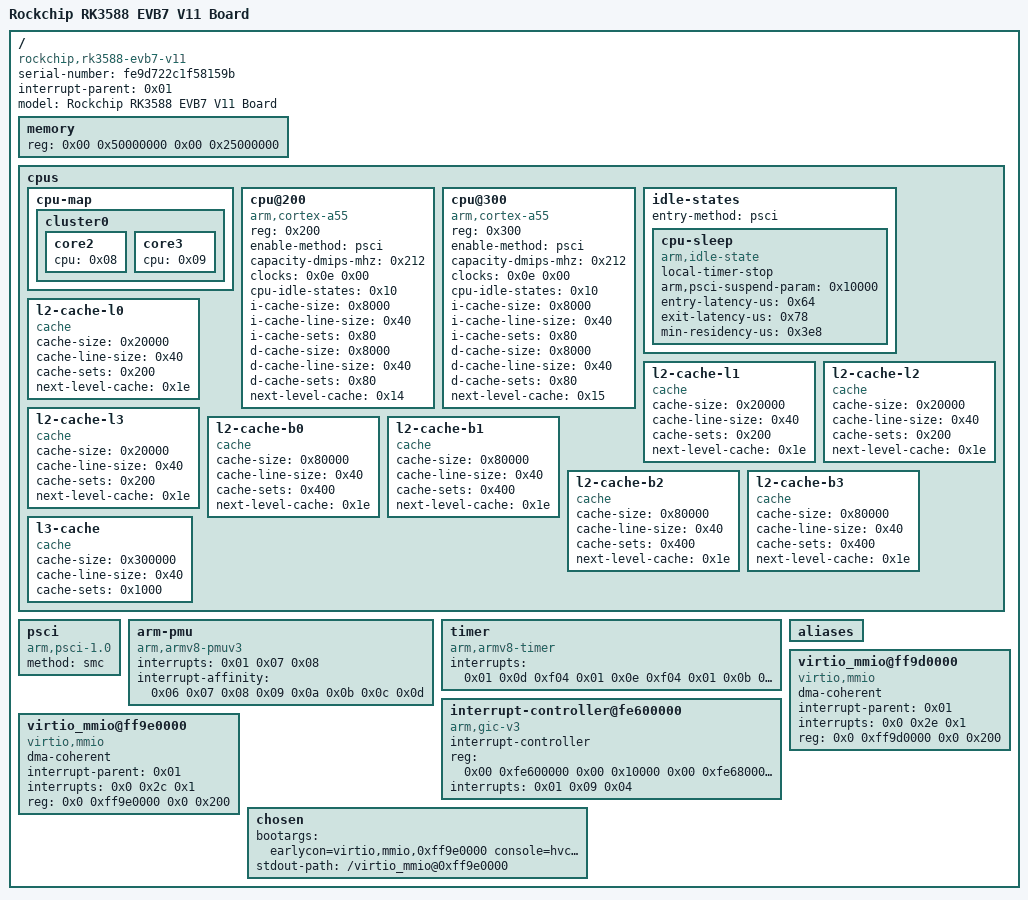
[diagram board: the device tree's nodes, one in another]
/dts-v1/;

/memreserve/	0x0000000008300000 0x0000000000047000;
/ {
	serial-number = "fe9d722c1f58159b";
	compatible = "rockchip,rk3588-evb7-v11\0rockchip,rk3588";
	interrupt-parent = <0x01>;
	#address-cells = <0x02>;
	#size-cells = <0x02>;
	model = "Rockchip RK3588 EVB7 V11 Board";

	memory {
		reg = <0x00 0x50000000 0x00 0x25000000>;
		device_type = "memory";
	};

	cpus {
		#address-cells = <0x01>;
		#size-cells = <0x00>;

		cpu-map {
			cluster0 {
				core2 {
					cpu = <0x08>;
				};
				core3 {
					cpu = <0x09>;
				};
			};
		};

		cpu@200 {
			device_type = "cpu";
			compatible = "arm,cortex-a55";
			reg = <0x200>;
			enable-method = "psci";
			capacity-dmips-mhz = <0x212>;
			clocks = <0x0e 0x00>;
			cpu-idle-states = <0x10>;
			i-cache-size = <0x8000>;
			i-cache-line-size = <0x40>;
			i-cache-sets = <0x80>;
			d-cache-size = <0x8000>;
			d-cache-line-size = <0x40>;
			d-cache-sets = <0x80>;
			next-level-cache = <0x14>;
			phandle = <0x08>;
		};

		cpu@300 {
			device_type = "cpu";
			compatible = "arm,cortex-a55";
			reg = <0x300>;
			enable-method = "psci";
			capacity-dmips-mhz = <0x212>;
			clocks = <0x0e 0x00>;
			cpu-idle-states = <0x10>;
			i-cache-size = <0x8000>;
			i-cache-line-size = <0x40>;
			i-cache-sets = <0x80>;
			d-cache-size = <0x8000>;
			d-cache-line-size = <0x40>;
			d-cache-sets = <0x80>;
			next-level-cache = <0x15>;
			phandle = <0x09>;
		};

		idle-states {
			entry-method = "psci";
			cpu-sleep {
				compatible = "arm,idle-state";
				local-timer-stop;
				arm,psci-suspend-param = <0x10000>;
				entry-latency-us = <0x64>;
				exit-latency-us = <0x78>;
				min-residency-us = <0x3e8>;
				phandle = <0x10>;
			};
		};

		l2-cache-l0 {
			compatible = "cache";
			cache-size = <0x20000>;
			cache-line-size = <0x40>;
			cache-sets = <0x200>;
			next-level-cache = <0x1e>;
			phandle = <0x11>;
		};

		l2-cache-l1 {
			compatible = "cache";
			cache-size = <0x20000>;
			cache-line-size = <0x40>;
			cache-sets = <0x200>;
			next-level-cache = <0x1e>;
			phandle = <0x13>;
		};

		l2-cache-l2 {
			compatible = "cache";
			cache-size = <0x20000>;
			cache-line-size = <0x40>;
			cache-sets = <0x200>;
			next-level-cache = <0x1e>;
			phandle = <0x14>;
		};

		l2-cache-l3 {
			compatible = "cache";
			cache-size = <0x20000>;
			cache-line-size = <0x40>;
			cache-sets = <0x200>;
			next-level-cache = <0x1e>;
			phandle = <0x15>;
		};

		l2-cache-b0 {
			compatible = "cache";
			cache-size = <0x80000>;
			cache-line-size = <0x40>;
			cache-sets = <0x400>;
			next-level-cache = <0x1e>;
			phandle = <0x17>;
		};

		l2-cache-b1 {
			compatible = "cache";
			cache-size = <0x80000>;
			cache-line-size = <0x40>;
			cache-sets = <0x400>;
			next-level-cache = <0x1e>;
			phandle = <0x19>;
		};

		l2-cache-b2 {
			compatible = "cache";
			cache-size = <0x80000>;
			cache-line-size = <0x40>;
			cache-sets = <0x400>;
			next-level-cache = <0x1e>;
			phandle = <0x1b>;
		};

		l2-cache-b3 {
			compatible = "cache";
			cache-size = <0x80000>;
			cache-line-size = <0x40>;
			cache-sets = <0x400>;
			next-level-cache = <0x1e>;
			phandle = <0x1d>;
		};

		l3-cache {
			compatible = "cache";
			cache-size = <0x300000>;
			cache-line-size = <0x40>;
			cache-sets = <0x1000>;
			phandle = <0x1e>;
		};
	};

	psci {
		compatible = "arm,psci-1.0";
		method = "smc";
	};

	arm-pmu {
		compatible = "arm,armv8-pmuv3";
		interrupts = <0x01 0x07 0x08>;
		interrupt-affinity = <0x06 0x07 0x08 0x09 0x0a 0x0b 0x0c 0x0d>;
		phandle = <0x220>;
	};

	timer {
		compatible = "arm,armv8-timer";
		interrupts = <0x01 0x0d 0xf04 0x01 0x0e 0xf04 0x01 0x0b 0xf04 0x01 0x0a 0xf04>;
	};

	interrupt-controller@fe600000 {
		compatible = "arm,gic-v3";
		#interrupt-cells = <0x03>;
		#address-cells = <0x02>;
		#size-cells = <0x02>;
		ranges;
		interrupt-controller;
		reg = <0x00 0xfe600000 0x00 0x10000 0x00 0xfe680000 0x00 0x100000>;
		interrupts = <0x01 0x09 0x04>;
		phandle = <0x01>;
	};

	
    aliases {
	};

	// virtio blk
	virtio_mmio@ff9d0000 {
		dma-coherent;
		interrupt-parent = <0x01>;
		interrupts = <0x0 0x2e 0x1>;
		reg = <0x0 0xff9d0000 0x0 0x200>;
		compatible = "virtio,mmio";
	};

	// virtio serial
	virtio_mmio@ff9e0000 {
		dma-coherent;
		interrupt-parent = <0x01>;
		interrupts = <0x0 0x2c 0x1>;
		reg = <0x0 0xff9e0000 0x0 0x200>;
		compatible = "virtio,mmio";
	};


	// serial@feb50000 {
	// 	compatible = "rockchip,rk3588-uart\0snps,dw-apb-uart";
	// 	reg = <0x00 0xfeb50000 0x00 0x100>;
	// 	interrupts = <0x00 0x14d 0x04>;
	// 	//clocks = <0x02 0xbb 0x02 0xac>;
	// 	//clock-names = "baudclk\0apb_pclk";
	// 	reg-shift = <0x02>;
	// 	reg-io-width = <0x04>;
	// 	//pinctrl-names = "default";
	// 	//pinctrl-0 = <0x16d>;
	// 	status = "okay";
	// 	phandle = <0x2e2>;
	// };


		
    chosen {
		bootargs = "earlycon=virtio,mmio,0xff9e0000 console=hvc0 root=/dev/vda rootwait rw";
		stdout-path = "/virtio_mmio@0xff9e0000";
	};
};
